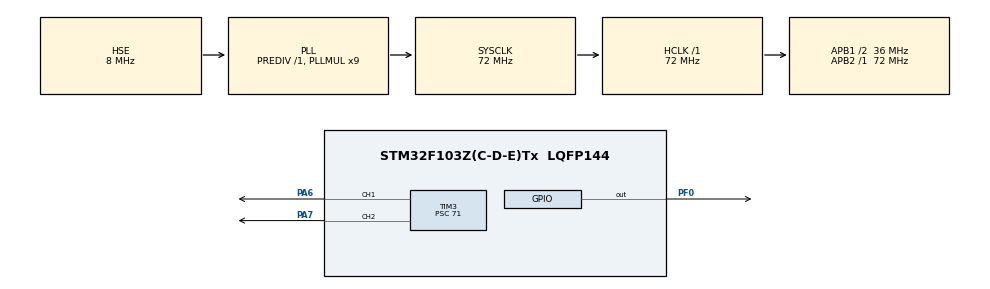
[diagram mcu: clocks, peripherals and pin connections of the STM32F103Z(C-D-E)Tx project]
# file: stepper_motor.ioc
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Mcu.Family=STM32F1
Mcu.Name=STM32F103Z(C-D-E)Tx
Mcu.Package=LQFP144
NVIC.PriorityGroup=NVIC_PRIORITYGROUP_4
NVIC.TIM3_IRQn=true\:0\:0\:false\:false\:true\:true\:true
NVIC.TIM4_IRQn=true\:0\:0\:false\:false\:true\:true\:true
OSC_IN.Mode=HSE-External-Oscillator
OSC_IN.Signal=RCC_OSC_IN
OSC_OUT.Mode=HSE-External-Oscillator
OSC_OUT.Signal=RCC_OSC_OUT
PA13.Mode=Serial_Wire
PA13.Signal=SYS_JTMS-SWDIO
PA14.Mode=Serial_Wire
PA14.Signal=SYS_JTCK-SWCLK
PA6.Signal=S_TIM3_CH1
PA7.Signal=S_TIM3_CH2
PF0.GPIO_PuPd=GPIO_PULLUP
PF0.GPIO_Speed=GPIO_SPEED_FREQ_MEDIUM
PF0.PinState=GPIO_PIN_SET
PF0.Signal=GPIO_Output
ProjectManager.HeapSize=0x200
ProjectManager.StackSize=0x400
ProjectManager.TargetToolchain=MDK-ARM V5.27
RCC.AHBFreq_Value=72000000
RCC.APB1CLKDivider=RCC_HCLK_DIV2
RCC.APB1Freq_Value=36000000
RCC.APB1TimFreq_Value=72000000
RCC.APB2Freq_Value=72000000
RCC.APB2TimFreq_Value=72000000
RCC.HCLKFreq_Value=72000000
RCC.PLLMUL=RCC_PLL_MUL9
RCC.PLLSourceVirtual=RCC_PLLSOURCE_HSE
RCC.SYSCLKFreq_VALUE=72000000
RCC.SYSCLKSource=RCC_SYSCLKSOURCE_PLLCLK
RCC.USBFreq_Value=72000000
SH.S_TIM3_CH1.0=TIM3_CH1,PWM Generation1 CH1
SH.S_TIM3_CH2.0=TIM3_CH2,PWM Generation2 CH2
TIM3.AutoReloadPreload=TIM_AUTORELOAD_PRELOAD_ENABLE
TIM3.Channel-PWM\ Generation1\ CH1=TIM_CHANNEL_1
TIM3.Channel-PWM\ Generation2\ CH2=TIM_CHANNEL_2
TIM3.Period=4999
TIM3.Prescaler=71
TIM4.AutoReloadPreload=TIM_AUTORELOAD_PRELOAD_DISABLE
TIM4.Period=4999
TIM4.Prescaler=71
VP_TIM3_VS_ClockSourceINT.Mode=Internal
VP_TIM4_VS_ClockSourceINT.Mode=Internal
board=custom

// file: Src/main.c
/* USER CODE BEGIN Header */
/**
  ******************************************************************************
  * @file           : main.c
  * @brief          : Main program body
  ******************************************************************************
  * @attention
  *
  * <h2><center>&copy; Copyright (c) 2021 STMicroelectronics.
  * All rights reserved.</center></h2>
  *
  * This software component is licensed by ST under BSD 3-Clause license,
  * the "License"; You may not use this file except in compliance with the
  * License. You may obtain a copy of the License at:
  *                        opensource.org/licenses/BSD-3-Clause
  *
  ******************************************************************************
  */
/* USER CODE END Header */
#include "main.h"
#include "tim.h"
#include "gpio.h"

/* USER CODE BEGIN Includes */
#include "stm32f1xx_it.h"
	int16_t i = 0;
/* USER CODE END Includes */

void SystemClock_Config(void);

int main(void)
{
  /* USER CODE BEGIN 1 */
float Angle = 0;
  /* USER CODE END 1 */

  /* MCU Configuration--------------------------------------------------------*/

  /* Reset of all peripherals, Initializes the Flash interface and the Systick. */
  HAL_Init();

  /* Configure the system clock */
  SystemClock_Config();

  /* Initialize all configured peripherals */
  MX_GPIO_Init();
  MX_TIM3_Init();
  MX_TIM4_Init();
  /* USER CODE BEGIN 2 */
  HAL_TIM_Base_Init (&htim3);
  __HAL_TIM_ENABLE_IT(&htim3,TIM_IT_UPDATE);
  HAL_TIM_Base_Start_IT(&htim3);
  HAL_TIM_PWM_Start(&htim3,TIM_CHANNEL_1);

    HAL_TIM_Base_Init (&htim4);
  __HAL_TIM_ENABLE_IT(&htim4,TIM_IT_UPDATE);
  HAL_TIM_Base_Start_IT(&htim4);
  Stepper_setInfo();
  /* USER CODE END 2 */

  /* Infinite loop */
  /* USER CODE BEGIN WHILE */
  while (1)
  {
	  Angle = 90;
	  Stepper_setAngle(&Angle);
	  //	  HAL_GPIO_WritePin(GPIOF,GPIO_PIN_0,GPIO_PIN_SET);
//if(0<_cnt&&_cnt<200){
//   __HAL_TIM_SetCompare(&htim3, TIM_CHANNEL_1,1);
//	_cnt++;}
//else{
//	_cnt =0;
//	if(i==0){
//	HAL_GPIO_TogglePin(GPIOA,GPIO_PIN_6);
//	i++;}
//
//
//	//HAL_GPIO_WritePin(GPIOA,GPIO_PIN_6,GPIO_PIN_SET);
//}
	  //htim3.State = !TIM_FLAG_UPDATE;
//	 if(i<800){
//     __HAL_TIM_SetCompare(&htim3, TIM_CHANNEL_1,1);
//	 i++;}
//	 else{
//	 __HAL_TIM_SetCompare(&htim3, TIM_CHANNEL_1,0);}
    /* USER CODE END WHILE */

  }
}

void SystemClock_Config(void)
{
  RCC_OscInitTypeDef RCC_OscInitStruct = {0};
  RCC_ClkInitTypeDef RCC_ClkInitStruct = {0};

  /** Initializes the RCC Oscillators according to the specified parameters
  * in the RCC_OscInitTypeDef structure.
  */
  RCC_OscInitStruct.OscillatorType = RCC_OSCILLATORTYPE_HSE;
  RCC_OscInitStruct.HSEState = RCC_HSE_ON;
  RCC_OscInitStruct.HSEPredivValue = RCC_HSE_PREDIV_DIV1;
  RCC_OscInitStruct.HSIState = RCC_HSI_ON;
  RCC_OscInitStruct.PLL.PLLState = RCC_PLL_ON;
  RCC_OscInitStruct.PLL.PLLSource = RCC_PLLSOURCE_HSE;
  RCC_OscInitStruct.PLL.PLLMUL = RCC_PLL_MUL9;
  if (HAL_RCC_OscConfig(&RCC_OscInitStruct) != HAL_OK)
  {
    Error_Handler();
  }
  /** Initializes the CPU, AHB and APB buses clocks
  */
  RCC_ClkInitStruct.ClockType = RCC_CLOCKTYPE_HCLK|RCC_CLOCKTYPE_SYSCLK
                              |RCC_CLOCKTYPE_PCLK1|RCC_CLOCKTYPE_PCLK2;
  RCC_ClkInitStruct.SYSCLKSource = RCC_SYSCLKSOURCE_PLLCLK;
  RCC_ClkInitStruct.AHBCLKDivider = RCC_SYSCLK_DIV1;
  RCC_ClkInitStruct.APB1CLKDivider = RCC_HCLK_DIV2;
  RCC_ClkInitStruct.APB2CLKDivider = RCC_HCLK_DIV1;

  if (HAL_RCC_ClockConfig(&RCC_ClkInitStruct, FLASH_LATENCY_2) != HAL_OK)
  {
    Error_Handler();
  }
}

void Error_Handler(void)
{
}

/************************ (C) COPYRIGHT STMicroelectronics *****END OF FILE****/
